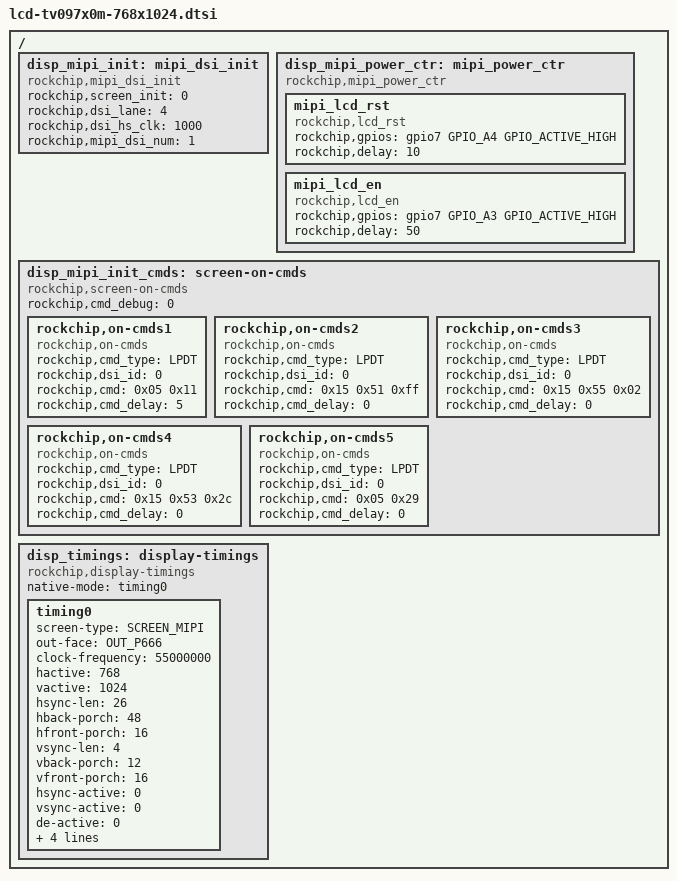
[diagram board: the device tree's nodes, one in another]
/*
 * Copyright (C) 2014 ROCKCHIP, Inc.
 * arch/arm/boot/dts/lcd-lq070m1sx01-mipi.dtsi
 * author: libing@rock-chips.com
 * create date: 2014-04-15
 * lcd model: lq070m1sx01
 * resolution: 1920 X 1200
 * mipi channel: dual 
 */

/ {
		/* about mipi */
		disp_mipi_init: mipi_dsi_init{
					compatible = "rockchip,mipi_dsi_init";
					rockchip,screen_init	= <0>;
					rockchip,dsi_lane		= <4>;
					rockchip,dsi_hs_clk		= <1000>;
					rockchip,mipi_dsi_num	= <1>;
		};
		disp_mipi_power_ctr: mipi_power_ctr {
					compatible = "rockchip,mipi_power_ctr";
					mipi_lcd_rst:mipi_lcd_rst{
							compatible = "rockchip,lcd_rst";
							rockchip,gpios = <&gpio7 GPIO_A4 GPIO_ACTIVE_HIGH>;
							rockchip,delay = <10>;
					};
					mipi_lcd_en:mipi_lcd_en {
							compatible = "rockchip,lcd_en";
							rockchip,gpios = <&gpio7 GPIO_A3 GPIO_ACTIVE_HIGH>;
							rockchip,delay = <50>;
					};
		};
		
		disp_mipi_init_cmds: screen-on-cmds {
					rockchip,cmd_debug = <0>;
					compatible = "rockchip,screen-on-cmds";
					rockchip,on-cmds1 {
							compatible = "rockchip,on-cmds";
							rockchip,cmd_type = <LPDT>;
							rockchip,dsi_id = <0>;
							rockchip,cmd = <0x05 0x11>;
							rockchip,cmd_delay = <5>;
					};
					
					rockchip,on-cmds2 {
							compatible = "rockchip,on-cmds";
							rockchip,cmd_type = <LPDT>;
							rockchip,dsi_id = <0>;
							rockchip,cmd = <0x15 0x51 0xff>;
							rockchip,cmd_delay = <0>;
					};
					rockchip,on-cmds3 {
							compatible = "rockchip,on-cmds";
							rockchip,cmd_type = <LPDT>;
							rockchip,dsi_id = <0>;
							rockchip,cmd = <0x15 0x55 0x02>;
							rockchip,cmd_delay = <0>;
					};
					rockchip,on-cmds4 {
							compatible = "rockchip,on-cmds";
							rockchip,cmd_type = <LPDT>;
							rockchip,dsi_id = <0>;
							rockchip,cmd = <0x15 0x53 0x2c>;
							rockchip,cmd_delay = <0>;
					};
					rockchip,on-cmds5 {
							compatible = "rockchip,on-cmds";
							rockchip,cmd_type = <LPDT>;
							rockchip,dsi_id = <0>;
							rockchip,cmd = <0x05 0x29 >;
							rockchip,cmd_delay = <0>;
					};
		};

		disp_timings: display-timings {
                        native-mode = <&timing0>;
                        compatible = "rockchip,display-timings";
                        timing0: timing0 {
				screen-type = <SCREEN_MIPI>;
				//lvds-format = <LVDS_8BIT_2>;
				out-face    = <OUT_P666>;
				clock-frequency = <55000000>;
				hactive = <768>;
				vactive = <1024>;
				hsync-len = <26>;
				hback-porch = <48>;
				hfront-porch = <16>;
				
				vsync-len = <4>;
				vback-porch = <12>;
				vfront-porch = <16>;
				
				hsync-active = <0>;
				vsync-active = <0>;
				de-active = <0>;
				pixelclk-active = <0>;
				swap-rb = <0>;
				swap-rg = <0>;
				swap-gb = <0>;
                     	};
               };
};
